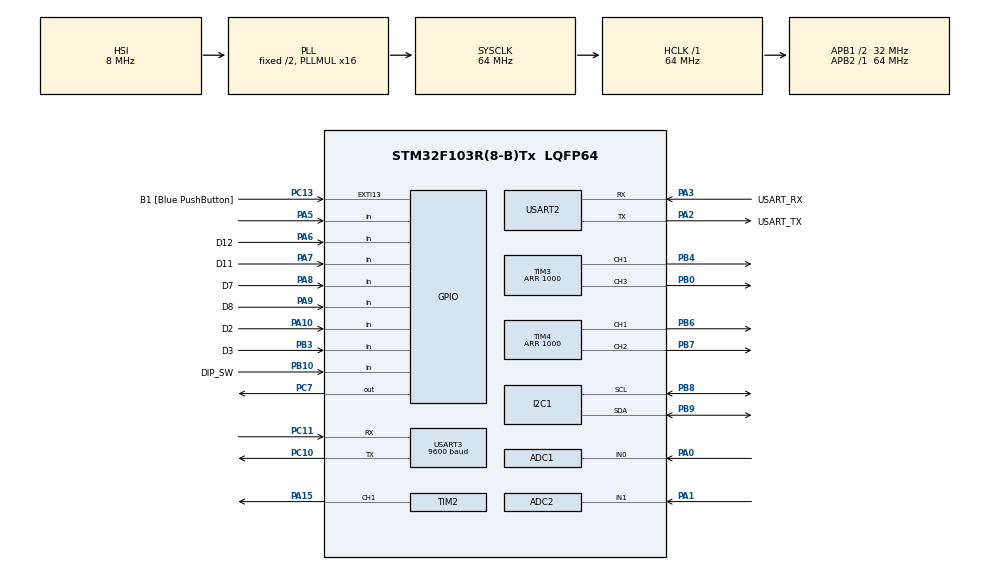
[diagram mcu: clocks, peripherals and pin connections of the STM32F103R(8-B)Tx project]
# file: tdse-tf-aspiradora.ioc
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ADC1.Channel-1\#ChannelRegularConversion=ADC_CHANNEL_0
ADC1.NbrOfConversionFlag=1
ADC1.Rank-1\#ChannelRegularConversion=1
ADC1.SamplingTime-1\#ChannelRegularConversion=ADC_SAMPLETIME_1CYCLE_5
ADC1.master=1
ADC2.Channel-0\#ChannelRegularConversion=ADC_CHANNEL_1
ADC2.NbrOfConversionFlag=1
ADC2.Rank-0\#ChannelRegularConversion=1
ADC2.SamplingTime-0\#ChannelRegularConversion=ADC_SAMPLETIME_1CYCLE_5
Mcu.Family=STM32F1
Mcu.Name=STM32F103R(8-B)Tx
Mcu.Package=LQFP64
NVIC.ADC1_2_IRQn=true\:0\:0\:false\:false\:true\:true\:true\:true
NVIC.EXTI15_10_IRQn=true\:0\:0\:false\:false\:true\:true\:true\:true
NVIC.PriorityGroup=NVIC_PRIORITYGROUP_4
NVIC.USART3_IRQn=true\:0\:0\:false\:false\:true\:true\:true\:true
PA0-WKUP.Signal=ADCx_IN0
PA1.Signal=ADCx_IN1
PA10.GPIO_Label=D2
PA10.GPIO_PuPd=GPIO_PULLUP
PA10.Signal=GPIO_Input
PA13.GPIO_Label=TMS
PA13.Mode=Serial_Wire
PA13.Signal=SYS_JTMS-SWDIO
PA14.GPIO_Label=TCK
PA14.Mode=Serial_Wire
PA14.Signal=SYS_JTCK-SWCLK
PA15.Signal=S_TIM2_CH1_ETR
PA2.GPIO_Label=USART_TX
PA2.GPIO_Mode=GPIO_MODE_AF_PP
PA2.GPIO_PuPd=GPIO_NOPULL
PA2.GPIO_Speed=GPIO_SPEED_FREQ_LOW
PA2.Mode=Asynchronous
PA2.Signal=USART2_TX
PA3.GPIO_Label=USART_RX
PA3.GPIO_Mode=GPIO_MODE_AF_PP
PA3.GPIO_PuPd=GPIO_NOPULL
PA3.GPIO_Speed=GPIO_SPEED_FREQ_LOW
PA3.Mode=Asynchronous
PA3.Signal=USART2_RX
PA5.Signal=GPIO_Input
PA6.GPIO_Label=D12
PA6.GPIO_PuPd=GPIO_PULLUP
PA6.Signal=GPIO_Input
PA7.GPIO_Label=D11
PA7.GPIO_PuPd=GPIO_PULLUP
PA7.Signal=GPIO_Input
PA8.GPIO_Label=D7
PA8.GPIO_PuPd=GPIO_PULLUP
PA8.Signal=GPIO_Input
PA9.GPIO_Label=D8
PA9.GPIO_PuPd=GPIO_PULLUP
PA9.Signal=GPIO_Input
PB0.Signal=S_TIM3_CH3
PB10.GPIO_Label=DIP_SW
PB10.GPIO_Mode=GPIO_MODE_INPUT
PB10.GPIO_PuPd=GPIO_PULLDOWN
PB10.Signal=GPIO_Input
PB3.GPIO_Label=D3
PB3.GPIO_PuPd=GPIO_PULLUP
PB3.Signal=GPIO_Input
PB4.Signal=S_TIM3_CH1
PB6.Signal=S_TIM4_CH1
PB7.Signal=S_TIM4_CH2
PB8.Mode=I2C
PB8.Signal=I2C1_SCL
PB9.Mode=I2C
PB9.Signal=I2C1_SDA
PC10.Mode=Asynchronous
PC10.Signal=USART3_TX
PC11.Mode=Asynchronous
PC11.Signal=USART3_RX
PC13-TAMPER-RTC.GPIO_Label=B1 [Blue PushButton]
PC13-TAMPER-RTC.GPIO_PuPd=GPIO_NOPULL
PC13-TAMPER-RTC.Signal=GPXTI13
PC14-OSC32_IN.Mode=LSE-External-Oscillator
PC14-OSC32_IN.Signal=RCC_OSC32_IN
PC15-OSC32_OUT.Mode=LSE-External-Oscillator
PC15-OSC32_OUT.Signal=RCC_OSC32_OUT
PC7.Signal=GPIO_Output
PD0-OSC_IN.Mode=HSE-External-Clock-Source
PD0-OSC_IN.Signal=RCC_OSC_IN
PD1-OSC_OUT.Mode=HSE-External-Clock-Source
PD1-OSC_OUT.Signal=RCC_OSC_OUT
ProjectManager.HeapSize=0x200
ProjectManager.StackSize=0x400
ProjectManager.TargetToolchain=STM32CubeIDE
RCC.ADCPresc=RCC_ADCPCLK2_DIV6
RCC.AHBFreq_Value=64000000
RCC.APB1CLKDivider=RCC_HCLK_DIV2
RCC.APB1Freq_Value=32000000
RCC.APB1TimFreq_Value=64000000
RCC.APB2Freq_Value=64000000
RCC.APB2TimFreq_Value=64000000
RCC.HCLKFreq_Value=64000000
RCC.PLLMUL=RCC_PLL_MUL16
RCC.RTCClockSelection=RCC_RTCCLKSOURCE_LSE
RCC.SYSCLKFreq_VALUE=64000000
RCC.SYSCLKSource=RCC_SYSCLKSOURCE_PLLCLK
RCC.USBFreq_Value=64000000
SH.ADCx_IN0.0=ADC1_IN0,IN0
SH.ADCx_IN1.0=ADC2_IN1,IN1
SH.S_TIM2_CH1_ETR.0=TIM2_CH1,PWM Generation1 CH1
SH.S_TIM3_CH1.0=TIM3_CH1,PWM Generation1 CH1
SH.S_TIM3_CH3.0=TIM3_CH3,PWM Generation3 CH3
SH.S_TIM4_CH1.0=TIM4_CH1,PWM Generation1 CH1
SH.S_TIM4_CH2.0=TIM4_CH2,PWM Generation2 CH2
TIM2.Channel-PWM\ Generation1\ CH1=TIM_CHANNEL_1
TIM2.Period=100-1
TIM2.Prescaler=72-1
TIM3.Channel-PWM\ Generation1\ CH1=TIM_CHANNEL_1
TIM3.Channel-PWM\ Generation3\ CH3=TIM_CHANNEL_3
TIM3.Period=1000
TIM4.Channel-PWM\ Generation1\ CH1=TIM_CHANNEL_1
TIM4.Channel-PWM\ Generation2\ CH2=TIM_CHANNEL_2
TIM4.Period=1000
USART2.VirtualMode=VM_ASYNC
USART3.BaudRate=9600
USART3.VirtualMode=VM_ASYNC
VP_TIM2_VS_ClockSourceINT.Mode=Internal
board=NUCLEO-F103RB

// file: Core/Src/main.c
/* USER CODE BEGIN Header */
/**
  ******************************************************************************
  * @file           : main.c
  * @brief          : Main program body
  ******************************************************************************
  * @attention
  *
  * Copyright (c) 2026 STMicroelectronics.
  * All rights reserved.
  *
  * This software is licensed under terms that can be found in the LICENSE file
  * in the root directory of this software component.
  * If no LICENSE file comes with this software, it is provided AS-IS.
  *
  ******************************************************************************
  */
/* USER CODE END Header */
#include "main.h"

/* USER CODE BEGIN Includes */

/* Application includes */
#include "logger.h"
#include "app.h"
#include "task_bluetooth.h"
#include "task_bluetooth_attribute.h"
#include "task_bluetooth_interface.h"
/* USER CODE END Includes */

ADC_HandleTypeDef hadc1;
ADC_HandleTypeDef hadc2;

I2C_HandleTypeDef hi2c1;

TIM_HandleTypeDef htim2;
TIM_HandleTypeDef htim3;
TIM_HandleTypeDef htim4;

UART_HandleTypeDef huart2;
UART_HandleTypeDef huart3;

void SystemClock_Config(void);
static void MX_GPIO_Init(void);
static void MX_USART2_UART_Init(void);
static void MX_I2C1_Init(void);
static void MX_ADC1_Init(void);
static void MX_ADC2_Init(void);
static void MX_TIM3_Init(void);
static void MX_TIM4_Init(void);
static void MX_TIM2_Init(void);
static void MX_USART3_UART_Init(void);

/* USER CODE BEGIN 0 */
#if (1 == LOGGER_CONFIG_USE_SEMIHOSTING)

extern void initialise_monitor_handles(void);

#endif

/* USER CODE END 0 */

int main(void)
{

  /* USER CODE BEGIN 1 */
  #if (1 == LOGGER_CONFIG_USE_SEMIHOSTING)

	initialise_monitor_handles();

  #endif

  /* USER CODE END 1 */

  /* MCU Configuration--------------------------------------------------------*/

  /* Reset of all peripherals, Initializes the Flash interface and the Systick. */
  HAL_Init();

  /* Configure the system clock */
  SystemClock_Config();

  /* Initialize all configured peripherals */
  MX_GPIO_Init();
  MX_USART2_UART_Init();
  MX_I2C1_Init();
  MX_ADC1_Init();
  MX_ADC2_Init();
  MX_TIM3_Init();
  MX_TIM4_Init();
  MX_TIM2_Init();
  MX_USART3_UART_Init();
  /* USER CODE BEGIN 2 */

  /* ============================================================================== */
    /* FIX FINAL PA15: Forzamos la liberación del pin después de las inicializaciones */
    /* ============================================================================== */
    // Aseguramos el reloj del módulo AFIO
  //Descomenta estas lineas si no anda el parlantito__HAL_RCC_AFIO_CLK_ENABLE();

    // Apagamos el JTAG para liberar físicamente a PA15 de las garras de la depuración
    //Descomenta estas lineas si no anda el parlantito __HAL_AFIO_REMAP_SWJ_NOJTAG();

    // Le avisamos al registro AFIO que mueva el Canal 1 del TIM2 al pin PA15
   //Descomenta estas lineas si no anda el parlantito // __HAL_AFIO_REMAP_TIM2_PARTIAL_1();
    /* =========================================
     *
     */
  /* ============================================================================== */
  /* FIX SENIOR: RESOLUCIÓN DEL BUG DEL REGISTRO AFIO (FANTASMA DEL JTAG)         */
  /* Al inicializar I2C1 y TIM3, las librerías generadas por CubeMX sobrescriben  */
  /* el registro AFIO->MAPR accidentalmente, volviendo a encender los pines JTAG. */
  /* Esto secuestra los pines PB4 (D5) y PB3 (D3), impidiendo que el PWM funcione */
  /* y clavando los voltajes en alto. Con esta instrucción, forzamos al hardware  */
  /* a apagar el JTAG nuevamente para liberar nuestros pines.                     */
  /* ============================================================================== */
//  __HAL_AFIO_REMAP_SWJ_NOJTAG();

  /* Application Init */

  app_init();
 // pwm_init(); Esto lo comenté xq lo puse en app init en app.c
  /* USER CODE END 2 */

  /* Infinite loop */
  while (1)
  {

    /* USER CODE BEGIN 3 */
	//pwm_update(); lo comenté porque lo puse en app.c

    /* Application Update */
    app_update();
  }
  /* USER CODE END 3 */
}

void SystemClock_Config(void)
{
  RCC_OscInitTypeDef RCC_OscInitStruct = {0};
  RCC_ClkInitTypeDef RCC_ClkInitStruct = {0};
  RCC_PeriphCLKInitTypeDef PeriphClkInit = {0};

  /** Initializes the RCC Oscillators according to the specified parameters
  * in the RCC_OscInitTypeDef structure.
  */
  RCC_OscInitStruct.OscillatorType = RCC_OSCILLATORTYPE_HSI;
  RCC_OscInitStruct.HSIState = RCC_HSI_ON;
  RCC_OscInitStruct.HSICalibrationValue = RCC_HSICALIBRATION_DEFAULT;
  RCC_OscInitStruct.PLL.PLLState = RCC_PLL_ON;
  RCC_OscInitStruct.PLL.PLLSource = RCC_PLLSOURCE_HSI_DIV2;
  RCC_OscInitStruct.PLL.PLLMUL = RCC_PLL_MUL16;
  if (HAL_RCC_OscConfig(&RCC_OscInitStruct) != HAL_OK)
  {
    Error_Handler();
  }

  /** Initializes the CPU, AHB and APB buses clocks
  */
  RCC_ClkInitStruct.ClockType = RCC_CLOCKTYPE_HCLK|RCC_CLOCKTYPE_SYSCLK
                              |RCC_CLOCKTYPE_PCLK1|RCC_CLOCKTYPE_PCLK2;
  RCC_ClkInitStruct.SYSCLKSource = RCC_SYSCLKSOURCE_PLLCLK;
  RCC_ClkInitStruct.AHBCLKDivider = RCC_SYSCLK_DIV1;
  RCC_ClkInitStruct.APB1CLKDivider = RCC_HCLK_DIV2;
  RCC_ClkInitStruct.APB2CLKDivider = RCC_HCLK_DIV1;

  if (HAL_RCC_ClockConfig(&RCC_ClkInitStruct, FLASH_LATENCY_2) != HAL_OK)
  {
    Error_Handler();
  }
  PeriphClkInit.PeriphClockSelection = RCC_PERIPHCLK_ADC;
  PeriphClkInit.AdcClockSelection = RCC_ADCPCLK2_DIV6;
  if (HAL_RCCEx_PeriphCLKConfig(&PeriphClkInit) != HAL_OK)
  {
    Error_Handler();
  }
}

static void MX_ADC1_Init(void)
{

  ADC_ChannelConfTypeDef sConfig = {0};

  /** Common config
  */
  hadc1.Instance = ADC1;
  hadc1.Init.ScanConvMode = ADC_SCAN_DISABLE;
  hadc1.Init.ContinuousConvMode = DISABLE;
  hadc1.Init.DiscontinuousConvMode = DISABLE;
  hadc1.Init.ExternalTrigConv = ADC_SOFTWARE_START;
  hadc1.Init.DataAlign = ADC_DATAALIGN_RIGHT;
  hadc1.Init.NbrOfConversion = 1;
  if (HAL_ADC_Init(&hadc1) != HAL_OK)
  {
    Error_Handler();
  }

  /** Configure Regular Channel
  */
  sConfig.Channel = ADC_CHANNEL_0;
  sConfig.Rank = ADC_REGULAR_RANK_1;
  sConfig.SamplingTime = ADC_SAMPLETIME_1CYCLE_5;
  if (HAL_ADC_ConfigChannel(&hadc1, &sConfig) != HAL_OK)
  {
    Error_Handler();
  }

}

static void MX_ADC2_Init(void)
{

  ADC_ChannelConfTypeDef sConfig = {0};

  /** Common config
  */
  hadc2.Instance = ADC2;
  hadc2.Init.ScanConvMode = ADC_SCAN_DISABLE;
  hadc2.Init.ContinuousConvMode = DISABLE;
  hadc2.Init.DiscontinuousConvMode = DISABLE;
  hadc2.Init.ExternalTrigConv = ADC_SOFTWARE_START;
  hadc2.Init.DataAlign = ADC_DATAALIGN_RIGHT;
  hadc2.Init.NbrOfConversion = 1;
  if (HAL_ADC_Init(&hadc2) != HAL_OK)
  {
    Error_Handler();
  }

  /** Configure Regular Channel
  */
  sConfig.Channel = ADC_CHANNEL_1;
  sConfig.Rank = ADC_REGULAR_RANK_1;
  sConfig.SamplingTime = ADC_SAMPLETIME_1CYCLE_5;
  if (HAL_ADC_ConfigChannel(&hadc2, &sConfig) != HAL_OK)
  {
    Error_Handler();
  }

}

static void MX_I2C1_Init(void)
{

  hi2c1.Instance = I2C1;
  hi2c1.Init.ClockSpeed = 100000;
  hi2c1.Init.DutyCycle = I2C_DUTYCYCLE_2;
  hi2c1.Init.OwnAddress1 = 0;
  hi2c1.Init.AddressingMode = I2C_ADDRESSINGMODE_7BIT;
  hi2c1.Init.DualAddressMode = I2C_DUALADDRESS_DISABLE;
  hi2c1.Init.OwnAddress2 = 0;
  hi2c1.Init.GeneralCallMode = I2C_GENERALCALL_DISABLE;
  hi2c1.Init.NoStretchMode = I2C_NOSTRETCH_DISABLE;
  if (HAL_I2C_Init(&hi2c1) != HAL_OK)
  {
    Error_Handler();
  }

}

static void MX_TIM2_Init(void)
{

  TIM_ClockConfigTypeDef sClockSourceConfig = {0};
  TIM_MasterConfigTypeDef sMasterConfig = {0};
  TIM_OC_InitTypeDef sConfigOC = {0};

  htim2.Instance = TIM2;
  htim2.Init.Prescaler = 72-1;
  htim2.Init.CounterMode = TIM_COUNTERMODE_UP;
  htim2.Init.Period = 100-1;
  htim2.Init.ClockDivision = TIM_CLOCKDIVISION_DIV1;
  htim2.Init.AutoReloadPreload = TIM_AUTORELOAD_PRELOAD_DISABLE;
  if (HAL_TIM_Base_Init(&htim2) != HAL_OK)
  {
    Error_Handler();
  }
  sClockSourceConfig.ClockSource = TIM_CLOCKSOURCE_INTERNAL;
  if (HAL_TIM_ConfigClockSource(&htim2, &sClockSourceConfig) != HAL_OK)
  {
    Error_Handler();
  }
  if (HAL_TIM_PWM_Init(&htim2) != HAL_OK)
  {
    Error_Handler();
  }
  sMasterConfig.MasterOutputTrigger = TIM_TRGO_RESET;
  sMasterConfig.MasterSlaveMode = TIM_MASTERSLAVEMODE_DISABLE;
  if (HAL_TIMEx_MasterConfigSynchronization(&htim2, &sMasterConfig) != HAL_OK)
  {
    Error_Handler();
  }
  sConfigOC.OCMode = TIM_OCMODE_PWM1;
  sConfigOC.Pulse = 0;
  sConfigOC.OCPolarity = TIM_OCPOLARITY_HIGH;
  sConfigOC.OCFastMode = TIM_OCFAST_DISABLE;
  if (HAL_TIM_PWM_ConfigChannel(&htim2, &sConfigOC, TIM_CHANNEL_1) != HAL_OK)
  {
    Error_Handler();
  }
  HAL_TIM_MspPostInit(&htim2);

}

static void MX_TIM3_Init(void)
{

  TIM_MasterConfigTypeDef sMasterConfig = {0};
  TIM_OC_InitTypeDef sConfigOC = {0};

  htim3.Instance = TIM3;
  htim3.Init.Prescaler = 0;
  htim3.Init.CounterMode = TIM_COUNTERMODE_UP;
  htim3.Init.Period = 1000;
  htim3.Init.ClockDivision = TIM_CLOCKDIVISION_DIV1;
  htim3.Init.AutoReloadPreload = TIM_AUTORELOAD_PRELOAD_DISABLE;
  if (HAL_TIM_PWM_Init(&htim3) != HAL_OK)
  {
    Error_Handler();
  }
  sMasterConfig.MasterOutputTrigger = TIM_TRGO_RESET;
  sMasterConfig.MasterSlaveMode = TIM_MASTERSLAVEMODE_DISABLE;
  if (HAL_TIMEx_MasterConfigSynchronization(&htim3, &sMasterConfig) != HAL_OK)
  {
    Error_Handler();
  }
  sConfigOC.OCMode = TIM_OCMODE_PWM1;
  sConfigOC.Pulse = 0;
  sConfigOC.OCPolarity = TIM_OCPOLARITY_HIGH;
  sConfigOC.OCFastMode = TIM_OCFAST_DISABLE;
  if (HAL_TIM_PWM_ConfigChannel(&htim3, &sConfigOC, TIM_CHANNEL_1) != HAL_OK)
  {
    Error_Handler();
  }
  if (HAL_TIM_PWM_ConfigChannel(&htim3, &sConfigOC, TIM_CHANNEL_3) != HAL_OK)
  {
    Error_Handler();
  }
  HAL_TIM_MspPostInit(&htim3);

}

static void MX_TIM4_Init(void)
{

  TIM_MasterConfigTypeDef sMasterConfig = {0};
  TIM_OC_InitTypeDef sConfigOC = {0};

  htim4.Instance = TIM4;
  htim4.Init.Prescaler = 0;
  htim4.Init.CounterMode = TIM_COUNTERMODE_UP;
  htim4.Init.Period = 1000;
  htim4.Init.ClockDivision = TIM_CLOCKDIVISION_DIV1;
  htim4.Init.AutoReloadPreload = TIM_AUTORELOAD_PRELOAD_DISABLE;
  if (HAL_TIM_PWM_Init(&htim4) != HAL_OK)
  {
    Error_Handler();
  }
  sMasterConfig.MasterOutputTrigger = TIM_TRGO_RESET;
  sMasterConfig.MasterSlaveMode = TIM_MASTERSLAVEMODE_DISABLE;
  if (HAL_TIMEx_MasterConfigSynchronization(&htim4, &sMasterConfig) != HAL_OK)
  {
    Error_Handler();
  }
  sConfigOC.OCMode = TIM_OCMODE_PWM1;
  sConfigOC.Pulse = 0;
  sConfigOC.OCPolarity = TIM_OCPOLARITY_HIGH;
  sConfigOC.OCFastMode = TIM_OCFAST_DISABLE;
  if (HAL_TIM_PWM_ConfigChannel(&htim4, &sConfigOC, TIM_CHANNEL_1) != HAL_OK)
  {
    Error_Handler();
  }
  if (HAL_TIM_PWM_ConfigChannel(&htim4, &sConfigOC, TIM_CHANNEL_2) != HAL_OK)
  {
    Error_Handler();
  }
  HAL_TIM_MspPostInit(&htim4);

}

static void MX_USART2_UART_Init(void)
{

  huart2.Instance = USART2;
  huart2.Init.BaudRate = 115200;
  huart2.Init.WordLength = UART_WORDLENGTH_8B;
  huart2.Init.StopBits = UART_STOPBITS_1;
  huart2.Init.Parity = UART_PARITY_NONE;
  huart2.Init.Mode = UART_MODE_TX_RX;
  huart2.Init.HwFlowCtl = UART_HWCONTROL_NONE;
  huart2.Init.OverSampling = UART_OVERSAMPLING_16;
  if (HAL_UART_Init(&huart2) != HAL_OK)
  {
    Error_Handler();
  }

}

static void MX_USART3_UART_Init(void)
{

  huart3.Instance = USART3;
  huart3.Init.BaudRate = 9600;
  huart3.Init.WordLength = UART_WORDLENGTH_8B;
  huart3.Init.StopBits = UART_STOPBITS_1;
  huart3.Init.Parity = UART_PARITY_NONE;
  huart3.Init.Mode = UART_MODE_TX_RX;
  huart3.Init.HwFlowCtl = UART_HWCONTROL_NONE;
  huart3.Init.OverSampling = UART_OVERSAMPLING_16;
  if (HAL_UART_Init(&huart3) != HAL_OK)
  {
    Error_Handler();
  }

}

static void MX_GPIO_Init(void)
{
  GPIO_InitTypeDef GPIO_InitStruct = {0};

  /* GPIO Ports Clock Enable */
  __HAL_RCC_GPIOC_CLK_ENABLE();
  __HAL_RCC_GPIOD_CLK_ENABLE();
  __HAL_RCC_GPIOA_CLK_ENABLE();
  __HAL_RCC_GPIOB_CLK_ENABLE();

  /*Configure GPIO pin Output Level */
  HAL_GPIO_WritePin(GPIOC, GPIO_PIN_7, GPIO_PIN_RESET);

  /*Configure GPIO pin : B1_Pin */
  GPIO_InitStruct.Pin = B1_Pin;
  GPIO_InitStruct.Mode = GPIO_MODE_IT_RISING;
  GPIO_InitStruct.Pull = GPIO_NOPULL;
  HAL_GPIO_Init(B1_GPIO_Port, &GPIO_InitStruct);

  /*Configure GPIO pin : PA5 */
  GPIO_InitStruct.Pin = GPIO_PIN_5;
  GPIO_InitStruct.Mode = GPIO_MODE_INPUT;
  GPIO_InitStruct.Pull = GPIO_NOPULL;
  HAL_GPIO_Init(GPIOA, &GPIO_InitStruct);

  /*Configure GPIO pins : D12_Pin D11_Pin D7_Pin D8_Pin
                           D2_Pin */
  GPIO_InitStruct.Pin = D12_Pin|D11_Pin|D7_Pin|D8_Pin
                          |D2_Pin;
  GPIO_InitStruct.Mode = GPIO_MODE_INPUT;
  GPIO_InitStruct.Pull = GPIO_PULLUP;
  HAL_GPIO_Init(GPIOA, &GPIO_InitStruct);

  /*Configure GPIO pin : DIP_SW_Pin */
  GPIO_InitStruct.Pin = DIP_SW_Pin;
  GPIO_InitStruct.Mode = GPIO_MODE_INPUT;
  GPIO_InitStruct.Pull = GPIO_PULLDOWN;
  HAL_GPIO_Init(DIP_SW_GPIO_Port, &GPIO_InitStruct);

  /*Configure GPIO pin : PC7 */
  GPIO_InitStruct.Pin = GPIO_PIN_7;
  GPIO_InitStruct.Mode = GPIO_MODE_OUTPUT_PP;
  GPIO_InitStruct.Pull = GPIO_NOPULL;
  GPIO_InitStruct.Speed = GPIO_SPEED_FREQ_LOW;
  HAL_GPIO_Init(GPIOC, &GPIO_InitStruct);

  /*Configure GPIO pin : D3_Pin */
  GPIO_InitStruct.Pin = D3_Pin;
  GPIO_InitStruct.Mode = GPIO_MODE_INPUT;
  GPIO_InitStruct.Pull = GPIO_PULLUP;
  HAL_GPIO_Init(D3_GPIO_Port, &GPIO_InitStruct);

  /* EXTI interrupt init*/
  HAL_NVIC_SetPriority(EXTI15_10_IRQn, 0, 0);
  HAL_NVIC_EnableIRQ(EXTI15_10_IRQn);

}

void Error_Handler(void)
{
  __disable_irq();
  while (1)
  {
  }
}
